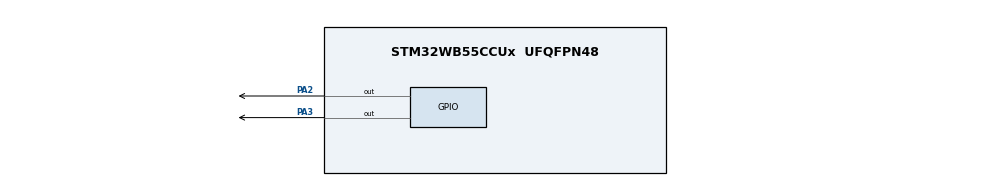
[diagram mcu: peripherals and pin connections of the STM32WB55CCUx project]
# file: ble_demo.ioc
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Mcu.Family=STM32WB
Mcu.Name=STM32WB55CCUx
Mcu.Package=UFQFPN48
NVIC.HSEM_IRQn=true\:0\:0\:false\:false\:true\:false\:true\:true
NVIC.IPCC_C1_RX_IRQn=true\:0\:0\:false\:false\:true\:true\:true\:true
NVIC.IPCC_C1_TX_IRQn=true\:0\:0\:false\:false\:true\:true\:true\:true
NVIC.PriorityGroup=NVIC_PRIORITYGROUP_4
NVIC.RTC_WKUP_IRQn=true\:0\:0\:false\:false\:true\:true\:true\:true
OSC_IN.Mode=HSE-External-Oscillator
OSC_IN.Signal=RCC_OSC_IN
OSC_OUT.Mode=HSE-External-Oscillator
OSC_OUT.Signal=RCC_OSC_OUT
PA2.Signal=GPIO_Output
PA3.Signal=GPIO_Output
PC14-OSC32_IN.Mode=LSE-External-Oscillator
PC14-OSC32_IN.Signal=RCC_OSC32_IN
PC15-OSC32_OUT.Mode=LSE-External-Oscillator
PC15-OSC32_OUT.Signal=RCC_OSC32_OUT
ProjectManager.HeapSize=0x200
ProjectManager.StackSize=0x400
ProjectManager.TargetToolchain=STM32CubeIDE
RCC.ADCFreq_Value=128000000
RCC.AHBFreq_Value=32000000
RCC.APB1Freq_Value=32000000
RCC.APB1TimFreq_Value=32000000
RCC.APB2Freq_Value=32000000
RCC.APB2TimFreq_Value=32000000
RCC.APB3Freq_Value=16000000
RCC.CortexFreq_Value=32000000
RCC.HCLKFreq_Value=32000000
RCC.HSE_VALUE=32000000
RCC.HSI48_VALUE=48000000
RCC.HSI_VALUE=16000000
RCC.MSIClockRange=RCC_MSIRANGE_10
RCC.SYSCLKFreq_VALUE=32000000
RCC.USBFreq_Value=128000000
RCC.VCOOutputFreq_Value=256000000
RF1.Mode=RF1_Activate
RF1.Signal=RF_RF1
STM32_WPAN.CFG_LSCLK_LSE=0
STM32_WPAN.CUSTOM_P2P_SERVER=Disabled
STM32_WPAN.CUSTOM_TEMPLATE=Enabled
STM32_WPAN.INCLUDE_AD_TYPE_COMPLETE_LOCAL_NAME=1
STM32_WPAN.NUMBER_OF_SERVICES=1
STM32_WPAN.SERVICE1_CHAR1_GATT_NOTIFY_READ_REQ_AND_WAIT_FOR_APPL_RESP=\ 
STM32_WPAN.SERVICE1_CHAR1_GATT_NOTIFY_WRITE_REQ_AND_WAIT_FOR_APPL_RESP=\ 
STM32_WPAN.SERVICE1_CHAR1_LONG_NAME=charwrite
STM32_WPAN.SERVICE1_CHAR1_PROP_WRITE=CHAR_PROP_WRITE
STM32_WPAN.SERVICE1_CHAR1_SHORT_NAME=charwrite
STM32_WPAN.SERVICE1_CHAR1_UUID=00 A2
STM32_WPAN.SERVICE1_CHAR1_VALUE_LENGTH=32
STM32_WPAN.SERVICE1_CHAR2_GATT_NOTIFY_ATTRIBUTE_WRITE=GATT_NOTIFY_ATTRIBUTE_WRITE
STM32_WPAN.SERVICE1_CHAR2_GATT_NOTIFY_READ_REQ_AND_WAIT_FOR_APPL_RESP=\ 
STM32_WPAN.SERVICE1_CHAR2_GATT_NOTIFY_WRITE_REQ_AND_WAIT_FOR_APPL_RESP=\ 
STM32_WPAN.SERVICE1_CHAR2_LONG_NAME=charnotify
STM32_WPAN.SERVICE1_CHAR2_PROP_NOTIFY=CHAR_PROP_NOTIFY
STM32_WPAN.SERVICE1_CHAR2_SHORT_NAME=charnotify
STM32_WPAN.SERVICE1_CHAR2_UUID=00 A1
STM32_WPAN.SERVICE1_CHAR2_VALUE_LENGTH=32
STM32_WPAN.SERVICE1_LONG_NAME=myService
STM32_WPAN.SERVICE1_NUMBER_OF_CHARACTERISTICS=2
STM32_WPAN.SERVICE1_SHORT_NAME=myService
STM32_WPAN.SERVICE1_UUID=00 01
VP_HSEM_VS_HSEM.Mode=HSEM_Activate
VP_IPCC_VS_IPCC.Mode=IPCC_Activate
VP_MEMORYMAP_VS_MEMORYMAP.Mode=CurAppReg
VP_RTC_VS_RTC_Activate.Mode=RTC_Enabled
VP_RTC_VS_RTC_WakeUp_intern.Mode=WakeUp
VP_SEQUENCER_VS_SEQUENCER.Mode=SEQUENCER_Enabled
VP_STM32_WPAN_VS_BLE_HOST.Mode=STM32_WPAN_Enabled
VP_TINY_LPM_VS_TINY_LPM.Mode=TINY_LPM_Enabled
board=custom

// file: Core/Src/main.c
/* USER CODE BEGIN Header */
/**
  ******************************************************************************
  * @file           : main.c
  * @brief          : Main program body
  ******************************************************************************
  * @attention
  *
  * Copyright (c) 2026 STMicroelectronics.
  * All rights reserved.
  *
  * This software is licensed under terms that can be found in the LICENSE file
  * in the root directory of this software component.
  * If no LICENSE file comes with this software, it is provided AS-IS.
  *
  ******************************************************************************
  */
/* USER CODE END Header */
#include "main.h"
#include "ipcc.h"
#include "rf.h"
#include "rtc.h"
#include "gpio.h"

/* USER CODE BEGIN Includes */
#include <string.h>
#include <math.h>
#include "custom_app.h"
/* USER CODE END Includes */

void SystemClock_Config(void);
void PeriphCommonClock_Config(void);

int main(void)
{

  /* MCU Configuration--------------------------------------------------------*/

  /* Reset of all peripherals, Initializes the Flash interface and the Systick. */
  HAL_Init();
  /* Config code for STM32_WPAN (HSE Tuning must be done before system clock configuration) */
  MX_APPE_Config();

  /* Configure the system clock */
  SystemClock_Config();

  /* Configure the peripherals common clocks */
  PeriphCommonClock_Config();

  /* IPCC initialisation */
  MX_IPCC_Init();

  /* Initialize all configured peripherals */
  MX_GPIO_Init();
  MX_RTC_Init();
  MX_RF_Init();

  /* Init code for STM32_WPAN */
  MX_APPE_Init();

  /* Infinite loop */
  /* USER CODE BEGIN WHILE */
  static uint16_t last_processed_length = 0;
  static uint8_t circle_angle = 0;
  static uint8_t is_cat_mode = 0;
  static uint8_t is_mouse_mode = 0;

  while (1)
  {
    MX_APPE_Process();

    /* USER CODE BEGIN 3 */

    /* Check last_received_message for "cat" or "mouse" */
    if (memcmp(last_received_message, "cat", 3) == 0 )
    {
      /* Start cat rotation mode */
      HAL_GPIO_WritePin(GPIOA, GPIO_PIN_2, GPIO_PIN_SET);
      last_processed_length = last_received_length;
      is_cat_mode = 1;
      is_mouse_mode = 0;
    }
    else if (memcmp(last_received_message, "mouse", 5) == 0)
    {
      /* Start mouse rotation mode */
      HAL_GPIO_WritePin(GPIOA, GPIO_PIN_2, GPIO_PIN_RESET);
      last_processed_length = last_received_length;
      is_cat_mode = 0;
      is_mouse_mode = 1;
    }

    /* Cat rotation: continuous update */
    if (is_cat_mode)
    {
      uint8_t center_x = 200;
      uint8_t center_y = 150;
      uint8_t radius = 50;

      float rad = (circle_angle * 3.14159f) / 180.0f;
      uint8_t cat_x = (uint8_t)(center_x + radius * cosf(rad));
      uint8_t cat_y = (uint8_t)(center_y + radius * sinf(rad));
      uint8_t mouse_x = center_x;
      uint8_t mouse_y = center_y;

      Custom_APP_Send_Position(cat_x, cat_y, circle_angle, mouse_x, mouse_y);
      circle_angle = (circle_angle + 5) % 360;
    }

    /* Mouse rotation: continuous update */
    if (is_mouse_mode)
    {
      uint8_t center_x = 200;
      uint8_t center_y = 150;
      uint8_t radius = 50;

      float rad = (circle_angle * 3.14159f) / 180.0f;
      uint8_t cat_x = center_x;
      uint8_t cat_y = center_y;
      uint8_t mouse_x = (uint8_t)(center_x + radius * cosf(rad));
      uint8_t mouse_y = (uint8_t)(center_y + radius * sinf(rad));

      Custom_APP_Send_Position(cat_x, cat_y, circle_angle, mouse_x, mouse_y);
      circle_angle = (circle_angle + 5) % 360;
    }
    HAL_Delay(100);

    /* USER CODE END 3 */
  }
}
  /* USER CODE END WHILE */

void SystemClock_Config(void)
{
  RCC_OscInitTypeDef RCC_OscInitStruct = {0};
  RCC_ClkInitTypeDef RCC_ClkInitStruct = {0};

  /** Configure the main internal regulator output voltage
  */
  __HAL_PWR_VOLTAGESCALING_CONFIG(PWR_REGULATOR_VOLTAGE_SCALE1);

  /** Initializes the RCC Oscillators according to the specified parameters
  * in the RCC_OscInitTypeDef structure.
  */
  RCC_OscInitStruct.OscillatorType = RCC_OSCILLATORTYPE_HSI|RCC_OSCILLATORTYPE_LSI1
                              |RCC_OSCILLATORTYPE_HSE|RCC_OSCILLATORTYPE_MSI;
  RCC_OscInitStruct.HSEState = RCC_HSE_ON;
  RCC_OscInitStruct.HSIState = RCC_HSI_ON;
  RCC_OscInitStruct.MSIState = RCC_MSI_ON;
  RCC_OscInitStruct.HSICalibrationValue = RCC_HSICALIBRATION_DEFAULT;
  RCC_OscInitStruct.MSICalibrationValue = RCC_MSICALIBRATION_DEFAULT;
  RCC_OscInitStruct.MSIClockRange = RCC_MSIRANGE_10;
  RCC_OscInitStruct.LSIState = RCC_LSI_ON;
  RCC_OscInitStruct.PLL.PLLState = RCC_PLL_NONE;
  if (HAL_RCC_OscConfig(&RCC_OscInitStruct) != HAL_OK)
  {
    Error_Handler();
  }

  /** Configure the SYSCLKSource, HCLK, PCLK1 and PCLK2 clocks dividers
  */
  RCC_ClkInitStruct.ClockType = RCC_CLOCKTYPE_HCLK4|RCC_CLOCKTYPE_HCLK2
                              |RCC_CLOCKTYPE_HCLK|RCC_CLOCKTYPE_SYSCLK
                              |RCC_CLOCKTYPE_PCLK1|RCC_CLOCKTYPE_PCLK2;
  RCC_ClkInitStruct.SYSCLKSource = RCC_SYSCLKSOURCE_MSI;
  RCC_ClkInitStruct.AHBCLKDivider = RCC_SYSCLK_DIV1;
  RCC_ClkInitStruct.APB1CLKDivider = RCC_HCLK_DIV1;
  RCC_ClkInitStruct.APB2CLKDivider = RCC_HCLK_DIV1;
  RCC_ClkInitStruct.AHBCLK2Divider = RCC_SYSCLK_DIV1;
  RCC_ClkInitStruct.AHBCLK4Divider = RCC_SYSCLK_DIV1;

  if (HAL_RCC_ClockConfig(&RCC_ClkInitStruct, FLASH_LATENCY_1) != HAL_OK)
  {
    Error_Handler();
  }
}

void PeriphCommonClock_Config(void)
{
  RCC_PeriphCLKInitTypeDef PeriphClkInitStruct = {0};

  /** Initializes the peripherals clock
  */
  PeriphClkInitStruct.PeriphClockSelection = RCC_PERIPHCLK_SMPS|RCC_PERIPHCLK_RFWAKEUP;
  PeriphClkInitStruct.RFWakeUpClockSelection = RCC_RFWKPCLKSOURCE_HSE_DIV1024;
  PeriphClkInitStruct.SmpsClockSelection = RCC_SMPSCLKSOURCE_HSI;
  PeriphClkInitStruct.SmpsDivSelection = RCC_SMPSCLKDIV_RANGE1;

  if (HAL_RCCEx_PeriphCLKConfig(&PeriphClkInitStruct) != HAL_OK)
  {
    Error_Handler();
  }
}

void Error_Handler(void)
{
  __disable_irq();
  while (1)
  {
  }
}
